# SIBG301M114KGH register map
Vendor: Silicon Labs; Series: Si; File version: B
Registers are 32-bit, read-write, reset 0x0 unless marked. A register's access mark holds for its fields unless they carry their own. Offsets are from the block's base; [hi:lo] are bit positions; lines under a group give offsets from that group; {n}, {i} and the like mark numbered series; 'fields as' and 'values as' point back to an identical list.

## GPIO_NS — GPIO_NS Registers
Base 0x4083C000
Same registers: GPIO_S 0x5083C000
0x00 IPVERSION ro reset 0x8
  [31:0] IPVERSION — ip version id
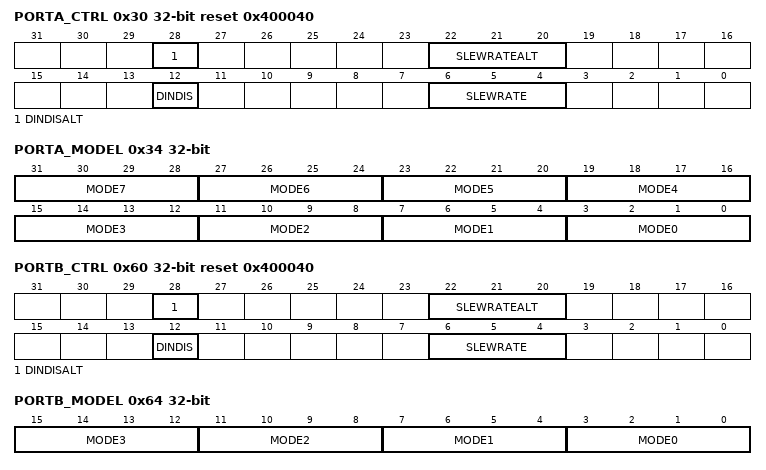
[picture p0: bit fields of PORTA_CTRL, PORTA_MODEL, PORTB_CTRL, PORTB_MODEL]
0x30 PORTA_CTRL reset 0x400040 — Port control
  [28] DINDISALT — Data In Disable Alt
  [22:20] SLEWRATEALT
  [12] DINDIS — Data In Disable
  [6:4] SLEWRATE
0x34 PORTA_MODEL — mode low
  [all] fields
    0=DISABLED (Input disabled. Pullup if DOUT is set.); 1=INPUT (Input enabled. Filter if DOUT is set.); 2=INPUTPULL (Input enabled. DOUT determines pull direction.); 3=INPUTPULLFILTER (Input enabled with filter. DOUT determines pull direction.); 4=PUSHPULL (Push-pull output.); 5=PUSHPULLALT (Push-pull using alternate control.); 6=WIREDOR (Wired-or output.); 7=WIREDORPULLDOWN (Wired-or output with pull-down.); 8=WIREDAND (Open-drain output.); 9=WIREDANDFILTER (Open-drain output with filter.); 10=WIREDANDPULLUP (Open-drain output with pullup.); 11=WIREDANDPULLUPFILTER (Open-drain output with filter and pullup.); 12=WIREDANDALT (Open-drain output using alternate control.); 13=WIREDANDALTFILTER (Open-drain output using alternate control with filter.); 14=WIREDANDALTPULLUP (Open-drain output using alternate control with pullup.); 15=WIREDANDALTPULLUPFILTER (Open-drain output using alternate control with filter and pullup.)
  [4n+3:4n] MODE{n} (n=0..7) — MODE n
0x3C PORTA_MODEH — mode high
  [3:0] MODE0 — MODE n
    values as the fields of PORTA_MODEL
0x40 PORTA_DOUT — data out
  [8:0] DOUT — Data output
0x44 PORTA_DIN ro — data in
  [8:0] DIN — Data input
0x48 PORTA_AMUXMODE — AMUXMODE
  [8:0] LNEN — Low Noise Enable
0x60 PORTB_CTRL reset 0x400040 — Port control
  fields as PORTA_CTRL
0x64 PORTB_MODEL — mode low
  [all] fields
    values as the fields of PORTA_MODEL
  [4n+3:4n] MODE{n} (n=0..3) — MODE n
0x70 PORTB_DOUT — data out
  [3:0] DOUT — Data output
0x74 PORTB_DIN ro — data in
  [3:0] DIN — Data input
0x78 PORTB_AMUXMODE — AMUXMODE
  [3:0] LNEN — Low Noise Enable
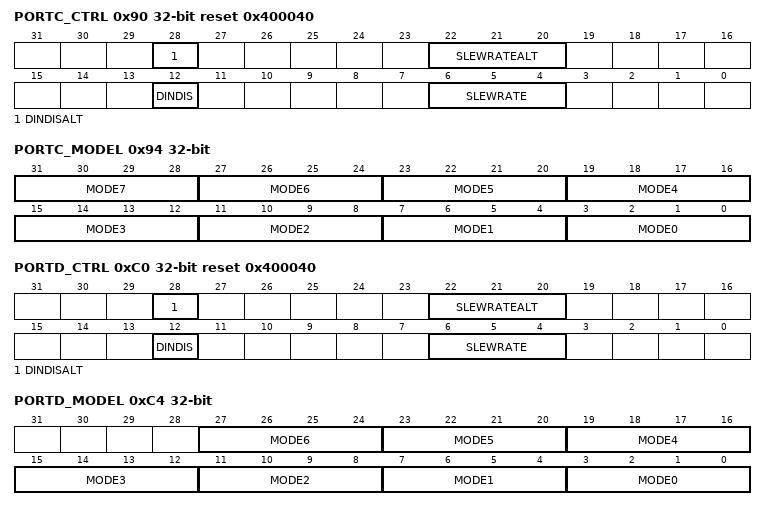
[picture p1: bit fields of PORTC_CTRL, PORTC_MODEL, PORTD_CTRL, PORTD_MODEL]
0x90 PORTC_CTRL reset 0x400040 — Port control
  fields as PORTA_CTRL
0x94 PORTC_MODEL — mode low
  fields as PORTA_MODEL
0xA0 PORTC_DOUT — data out
  [7:0] DOUT — Data output
0xA4 PORTC_DIN ro — data in
  [7:0] DIN — Data input
0xA8 PORTC_AMUXMODE — AMUXMODE
  [7:0] LNEN — Low Noise Enable
0xC0 PORTD_CTRL reset 0x400040 — Port control
  fields as PORTA_CTRL
0xC4 PORTD_MODEL — mode low
  [all] fields
    values as the fields of PORTA_MODEL
  [4n+3:4n] MODE{n} (n=0..6) — MODE n
0xD0 PORTD_DOUT — data out
  [6:0] DOUT — Data output
0xD4 PORTD_DIN ro — data in
  [6:0] DIN — Data input
0xD8 PORTD_AMUXMODE — AMUXMODE
  [6:0] LNEN — Low Noise Enable
0x300 LOCK wo reset 0xA534
  [15:0] LOCKKEY — Configuration Lock Key
    0xA534=UNLOCK (Unlock code)
0x310 GPIOLOCKSTATUS ro
  [0] LOCK — GPIO LOCK status
    0=UNLOCKED (Registers are unlocked); 1=LOCKED (Registers are locked)
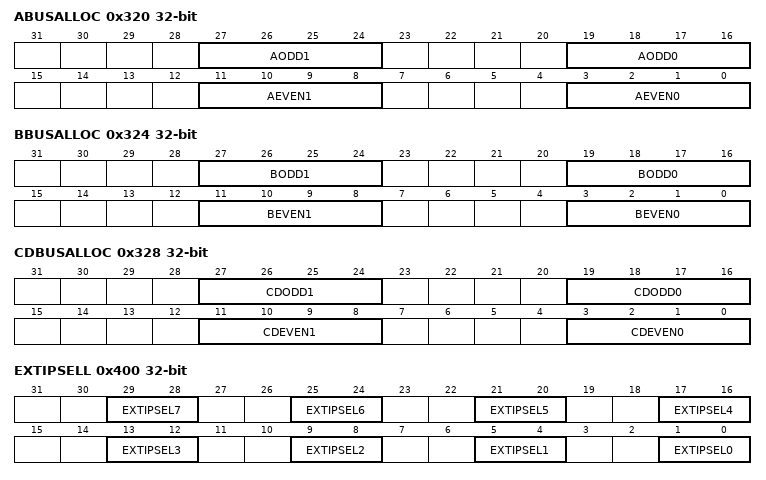
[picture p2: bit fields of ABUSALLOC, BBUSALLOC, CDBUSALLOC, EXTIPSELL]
0x320 ABUSALLOC — A Bus allocation
  [all] fields
    0=TRISTATE (The bus is not allocated); 1=ADC0 (The bus is allocated to ADC0); 2=ACMP0 (The bus is allocated to ACMP0); 3=ACMP1 (The bus is allocated to ACMP1)
  [27:24] AODD1 — A Bus Odd 1
  [19:16] AODD0 — A Bus Odd 0
  [11:8] AEVEN1 — A Bus Even 1
  [3:0] AEVEN0 — A Bus Even 0
0x324 BBUSALLOC — B Bus allocation
  [27:24] BODD1 — B Bus Odd 1
    0=TRISTATE (The bus is not allocated); 1=ADC0 (The bus is allocated to ADC0); 2=ACMP0 (The bus is allocated to ACMP0); 3=ACMP1 (The bus is allocated to ACMP1); 4=VDAC0CH1 (The bus is allocated to VDAC0 CH1); 5=VDAC1CH1 (The bus is allocated to VDAC1 CH1)
  [19:16] BODD0 — B Bus Odd 0
    0=TRISTATE (The bus is not allocated); 1=ADC0 (The bus is allocated to ADC0); 2=ACMP0 (The bus is allocated to ACMP0); 3=ACMP1 (The bus is allocated to ACMP1); 4=VDAC0CH0 (The bus is allocated to VDAC0 CH0); 5=VDAC1CH0 (The bus is allocated to VDAC1 CH0)
  [11:8] BEVEN1 — B Bus Even 1
    values as the fields of ABUSALLOC
  [3:0] BEVEN0 — B Bus Even 0
    0=TRISTATE (The bus is not allocated); 1=ADC0 (The bus is allocated to ADC0); 2=ACMP0 (The bus is allocated to ACMP0); 3=ACMP1 (The bus is allocated to ACMP1); 14=DIAGA (The bus is allocated to DIAGA)
0x328 CDBUSALLOC — CD Bus allocation
  [all] fields
    0=TRISTATE (The bus is not allocated); 1=ADC0 (The bus is allocated to ADC0); 2=ACMP0 (The bus is allocated to ACMP0); 3=ACMP1 (The bus is allocated to ACMP1); 4=LEDDRV (The bus is allocated to LEDDRV)
  [27:24] CDODD1 — CD Bus Odd 1
  [19:16] CDODD0 — CD Bus Odd 0
  [11:8] CDEVEN1 — CD Bus Even 1
  [3:0] CDEVEN0 — CD Bus Even 0
0x400 EXTIPSELL — External Interrupt Port Select Low
  [all] fields
    0=PORTA (Port A group selected); 1=PORTB (Port B group selected); 2=PORTC (Port C group selected); 3=PORTD (Port D group selected)
  [4n+1:4n] EXTIPSEL{n} (n=0..7) — External Interrupt Port Select
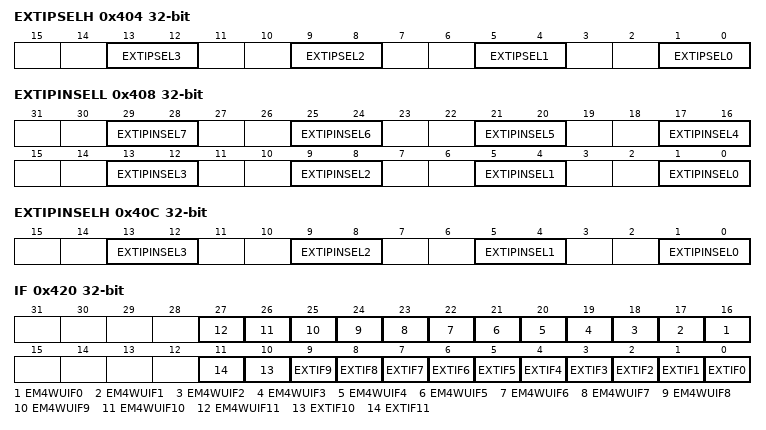
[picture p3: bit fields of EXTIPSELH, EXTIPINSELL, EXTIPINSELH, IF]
0x404 EXTIPSELH — External interrupt Port Select High
  [all] fields
    values as the fields of EXTIPSELL
  [4n+1:4n] EXTIPSEL{n} (n=0..3) — External Interrupt Port Select
0x408 EXTIPINSELL — External Interrupt Pin Select Low
  [all] fields
    {v}=PIN{v} (OFFSET={v}) (v=0..3)
  [4n+1:4n] EXTIPINSEL{n} (n=0..7) — External Interrupt Pin select
0x40C EXTIPINSELH — External Interrupt Pin Select High
  [all] fields
    {v}=PIN{v+8} (OFFSET={v+8}) (v=0..3)
  [4n+1:4n] EXTIPINSEL{n} (n=0..3) — External Interrupt Pin select
0x410 EXTIRISE — External Interrupt Rising Edge Trigger
  [11:0] EXTIRISE — EXT Int Rise
0x414 EXTIFALL — External Interrupt Falling Edge Trigger
  [11:0] EXTIFALL — EXT Int FALL
0x420 IF — Interrupt Flag
  [n+16] EM4WUIF{n} (n=0..11) — EM4 wake up
  [n] EXTIF{n} (n=0..11) — External Pin Flag
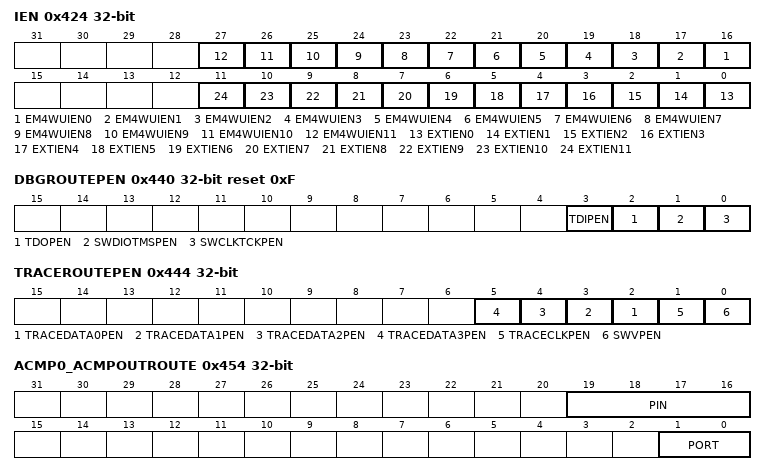
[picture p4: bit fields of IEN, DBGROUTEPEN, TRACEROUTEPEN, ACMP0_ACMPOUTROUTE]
0x424 IEN — Interrupt Enable
  [n+16] EM4WUIEN{n} (n=0..11) — EM4 Wake Up Interrupt En
  [n] EXTIEN{n} (n=0..11) — External Pin Enable
0x42C EM4WUEN
  [27:16] EM4WUEN — EM4 wake up enable
0x430 EM4WUPOL
  [27:16] EM4WUPOL — EM4 Wake-Up Polarity
0x440 DBGROUTEPEN reset 0xF
  [3] TDIPEN — JTAG Test Debug Input Pin Enable
  [2] TDOPEN — JTAG Test Debug Output Pin Enable
  [1] SWDIOTMSPEN — Route Location 0
  [0] SWCLKTCKPEN — Route Pin Enable
0x444 TRACEROUTEPEN
  [n+2] TRACEDATA{n}PEN (n=0..3) — Trace Data{n} Pin Enable
  [1] TRACECLKPEN — Trace Clk Pin Enable
  [0] SWVPEN — Serial Wire Viewer Output Pin Enable
0x450 ACMP0_ROUTEEN — ACMP0 pin enable
  [0] ACMPOUTPEN — ACMPOUT pin enable control bit
0x454 ACMP0_ACMPOUTROUTE — ACMPOUT port/pin select
  [19:16] PIN — ACMPOUT pin select register
  [1:0] PORT — ACMPOUT port select register
0x45C ACMP1_ROUTEEN — ACMP1 pin enable
  [0] ACMPOUTPEN — ACMPOUT pin enable control bit
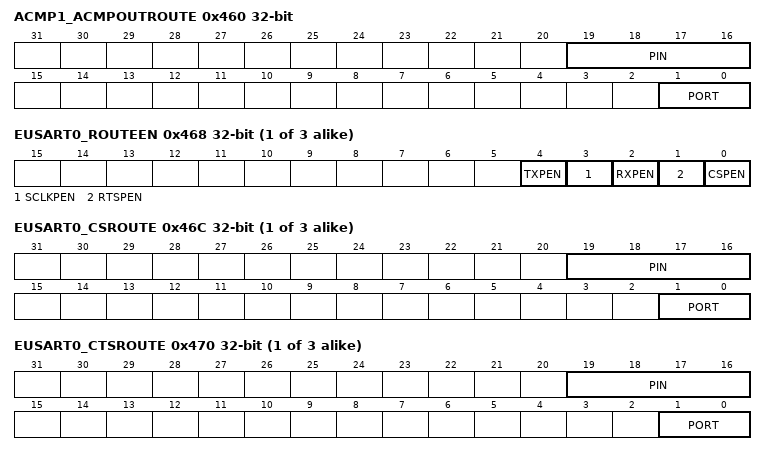
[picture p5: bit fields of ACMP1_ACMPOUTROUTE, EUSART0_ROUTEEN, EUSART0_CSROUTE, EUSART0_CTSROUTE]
0x460 ACMP1_ACMPOUTROUTE — ACMPOUT port/pin select
  fields as ACMP0_ACMPOUTROUTE
{0x468+0x20*i} EUSART{i}_ROUTEEN (i=0..2) — EUSART{i} pin enable
  [4] TXPEN — TX pin enable control bit
  [3] SCLKPEN — SCLK pin enable control bit
  [2] RXPEN — RX pin enable control bit
  [1] RTSPEN — RTS pin enable control bit
  [0] CSPEN — CS pin enable control bit
{0x46C+0x20*i} EUSART{i}_CSROUTE (i=0..2) — CS port/pin select
  [19:16] PIN — CS pin select register
  [1:0] PORT — CS port select register
{0x470+0x20*i} EUSART{i}_CTSROUTE (i=0..2) — CTS port/pin select
  [19:16] PIN — CTS pin select register
  [1:0] PORT — CTS port select register
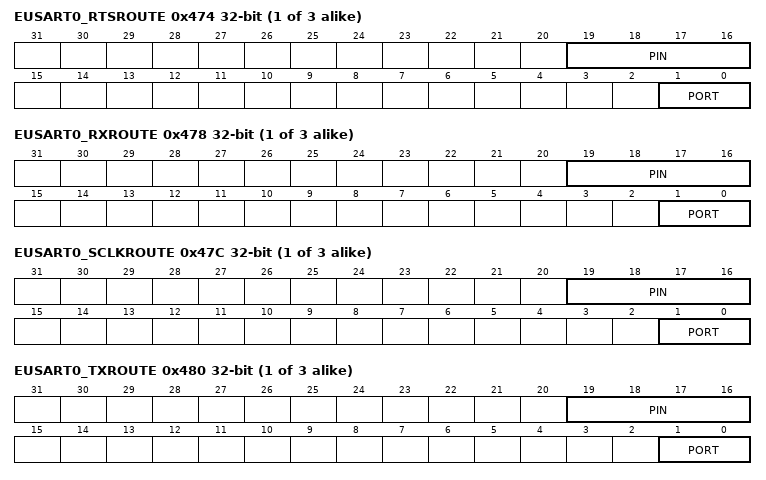
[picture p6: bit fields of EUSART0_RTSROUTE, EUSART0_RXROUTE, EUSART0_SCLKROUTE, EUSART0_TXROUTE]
{0x474+0x20*i} EUSART{i}_RTSROUTE (i=0..2) — RTS port/pin select
  [19:16] PIN — RTS pin select register
  [1:0] PORT — RTS port select register
{0x478+0x20*i} EUSART{i}_RXROUTE (i=0..2) — RX port/pin select
  [19:16] PIN — RX pin select register
  [1:0] PORT — RX port select register
{0x47C+0x20*i} EUSART{i}_SCLKROUTE (i=0..2) — SCLK port/pin select
  [19:16] PIN — SCLK pin select register
  [1:0] PORT — SCLK port select register
{0x480+0x20*i} EUSART{i}_TXROUTE (i=0..2) — TX port/pin select
  [19:16] PIN — TX pin select register
  [1:0] PORT — TX port select register
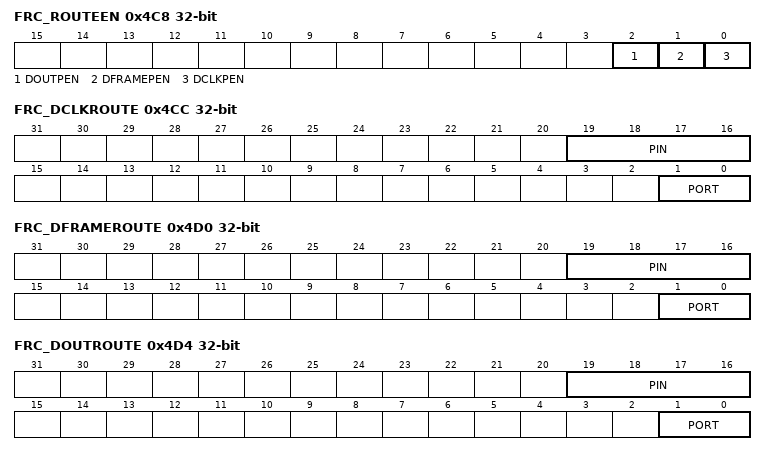
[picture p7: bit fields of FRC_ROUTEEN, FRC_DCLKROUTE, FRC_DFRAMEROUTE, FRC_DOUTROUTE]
0x4C8 FRC_ROUTEEN — FRC pin enable
  [2] DOUTPEN — DOUT pin enable control bit
  [1] DFRAMEPEN — DFRAME pin enable control bit
  [0] DCLKPEN — DCLK pin enable control bit
0x4CC FRC_DCLKROUTE — DCLK port/pin select
  [19:16] PIN — DCLK pin select register
  [1:0] PORT — DCLK port select register
0x4D0 FRC_DFRAMEROUTE — DFRAME port/pin select
  [19:16] PIN — DFRAME pin select register
  [1:0] PORT — DFRAME port select register
0x4D4 FRC_DOUTROUTE — DOUT port/pin select
  [19:16] PIN — DOUT pin select register
  [1:0] PORT — DOUT port select register
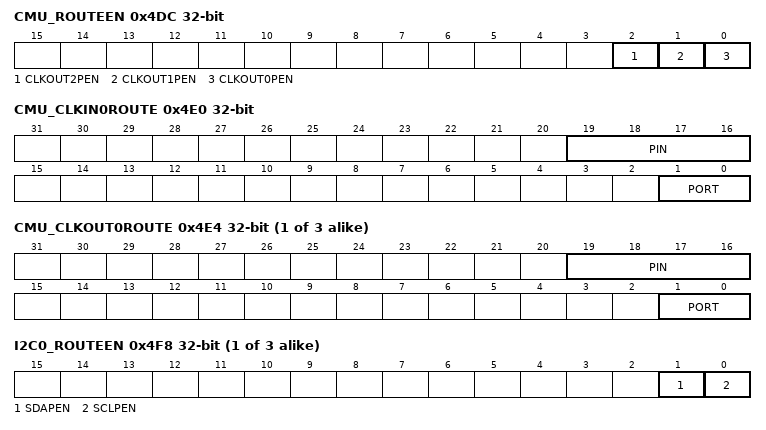
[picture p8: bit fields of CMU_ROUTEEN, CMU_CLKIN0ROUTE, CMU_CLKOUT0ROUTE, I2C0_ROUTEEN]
0x4DC CMU_ROUTEEN — HOSTCMU pin enable
  [2] CLKOUT2PEN — CLKOUT2 pin enable control bit
  [1] CLKOUT1PEN — CLKOUT1 pin enable control bit
  [0] CLKOUT0PEN — CLKOUT0 pin enable control bit
0x4E0 CMU_CLKIN0ROUTE — CLKIN0 port/pin select
  [19:16] PIN — CLKIN0 pin select register
  [1:0] PORT — CLKIN0 port select register
{0x4E4+4i} CMU_CLKOUT{i}ROUTE (i=0..2) — CLKOUT{i} port/pin select
  [19:16] PIN — CLKOUT{i} pin select register
  [1:0] PORT — CLKOUT{i} port select register
{0x4F8+0x10*i} I2C{i}_ROUTEEN (i=0..2) — I2C{i} pin enable
  [1] SDAPEN — SDA pin enable control bit
  [0] SCLPEN — SCL pin enable control bit
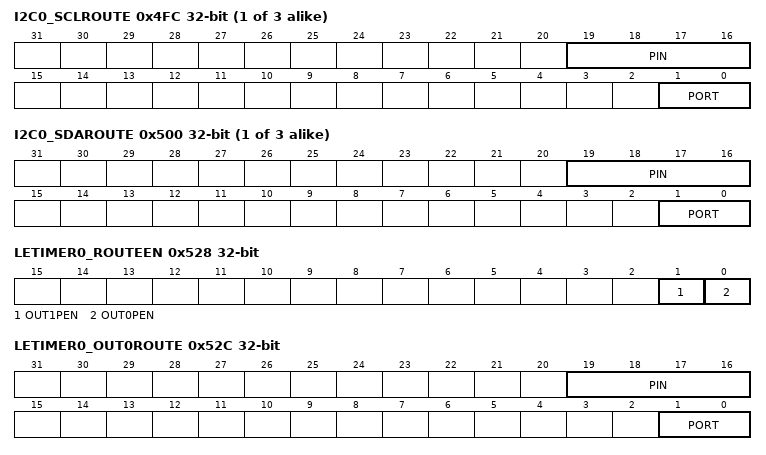
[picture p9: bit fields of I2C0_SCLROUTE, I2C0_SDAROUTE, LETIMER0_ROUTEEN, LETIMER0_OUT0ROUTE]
{0x4FC+0x10*i} I2C{i}_SCLROUTE (i=0..2) — SCL port/pin select
  [19:16] PIN — SCL pin select register
  [1:0] PORT — SCL port select register
{0x500+0x10*i} I2C{i}_SDAROUTE (i=0..2) — SDA port/pin select
  [19:16] PIN — SDA pin select register
  [1:0] PORT — SDA port select register
0x528 LETIMER0_ROUTEEN — LETIMER0 pin enable
  [1] OUT1PEN — OUT1 pin enable control bit
  [0] OUT0PEN — OUT0 pin enable control bit
0x52C LETIMER0_OUT0ROUTE — OUT0 port/pin select
  [19:16] PIN — OUT0 pin select register
  [1:0] PORT — OUT0 port select register
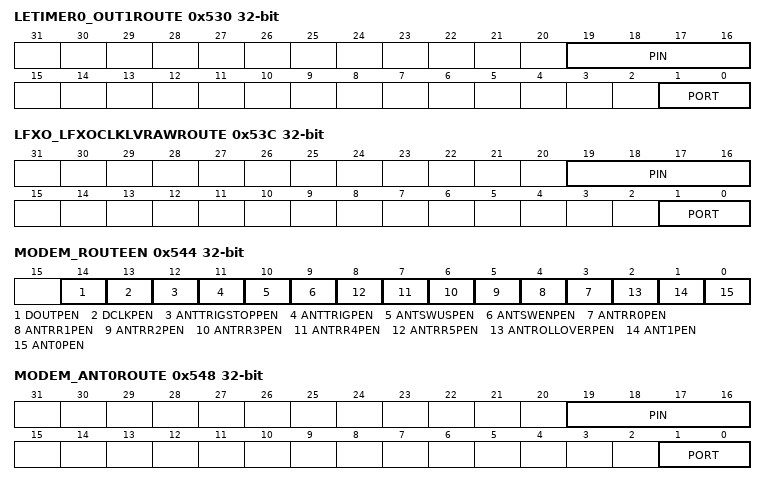
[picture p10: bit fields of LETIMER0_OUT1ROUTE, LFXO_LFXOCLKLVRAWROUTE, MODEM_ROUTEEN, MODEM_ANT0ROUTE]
0x530 LETIMER0_OUT1ROUTE — OUT1 port/pin select
  [19:16] PIN — OUT1 pin select register
  [1:0] PORT — OUT1 port select register
0x538 LFXO_ROUTEEN — LFXO pin enable
  [0] LFXOCLKLVRAWPEN — LFXOCLKLVRAW pin enable control bit
0x53C LFXO_LFXOCLKLVRAWROUTE — LFXOCLKLVRAW port/pin select
  [19:16] PIN — LFXOCLKLVRAW pin select register
  [1:0] PORT — LFXOCLKLVRAW port select register
0x544 MODEM_ROUTEEN — MODEM pin enable
  [14] DOUTPEN — DOUT pin enable control bit
  [13] DCLKPEN — DCLK pin enable control bit
  [12] ANTTRIGSTOPPEN — ANTTRIGSTOP pin enable control bit
  [11] ANTTRIGPEN — ANTTRIG pin enable control bit
  [10] ANTSWUSPEN — ANTSWUS pin enable control bit
  [9] ANTSWENPEN — ANTSWEN pin enable control bit
  [n+3] ANTRR{n}PEN (n=0..5) — ANTRR{n} pin enable control bit
  [2] ANTROLLOVERPEN — ANTROLLOVER pin enable control bit
  [1] ANT1PEN — ANT1 pin enable control bit
  [0] ANT0PEN — ANT0 pin enable control bit
0x548 MODEM_ANT0ROUTE — ANT0 port/pin select
  [19:16] PIN — ANT0 pin select register
  [1:0] PORT — ANT0 port select register
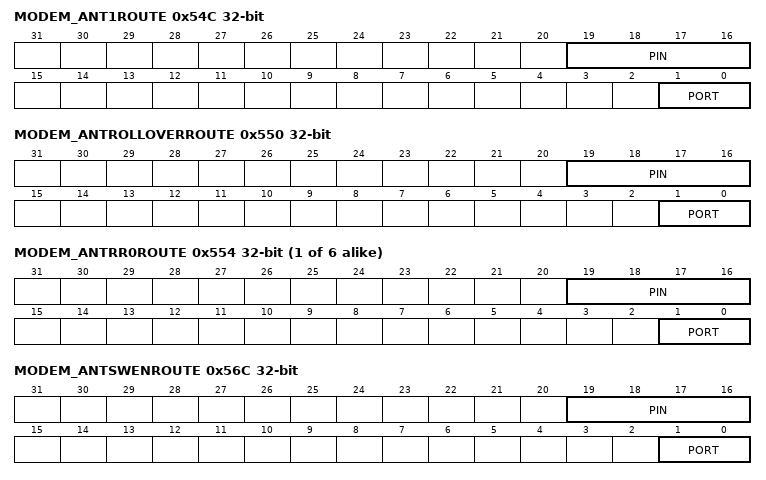
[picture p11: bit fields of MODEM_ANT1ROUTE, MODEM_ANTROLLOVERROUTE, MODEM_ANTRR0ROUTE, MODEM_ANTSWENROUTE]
0x54C MODEM_ANT1ROUTE — ANT1 port/pin select
  [19:16] PIN — ANT1 pin select register
  [1:0] PORT — ANT1 port select register
0x550 MODEM_ANTROLLOVERROUTE — ANTROLLOVER port/pin select
  [19:16] PIN — ANTROLLOVER pin select register
  [1:0] PORT — ANTROLLOVER port select register
{0x554+4i} MODEM_ANTRR{i}ROUTE (i=0..5) — ANTRR{i} port/pin select
  [19:16] PIN — ANTRR{i} pin select register
  [1:0] PORT — ANTRR{i} port select register
0x56C MODEM_ANTSWENROUTE — ANTSWEN port/pin select
  [19:16] PIN — ANTSWEN pin select register
  [1:0] PORT — ANTSWEN port select register
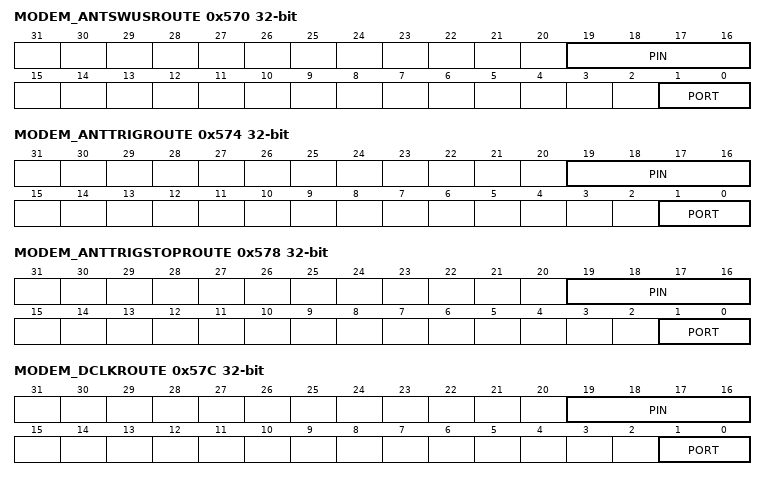
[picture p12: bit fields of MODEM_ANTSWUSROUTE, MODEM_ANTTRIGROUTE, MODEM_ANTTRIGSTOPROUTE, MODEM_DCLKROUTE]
0x570 MODEM_ANTSWUSROUTE — ANTSWUS port/pin select
  [19:16] PIN — ANTSWUS pin select register
  [1:0] PORT — ANTSWUS port select register
0x574 MODEM_ANTTRIGROUTE — ANTTRIG port/pin select
  [19:16] PIN — ANTTRIG pin select register
  [1:0] PORT — ANTTRIG port select register
0x578 MODEM_ANTTRIGSTOPROUTE — ANTTRIGSTOP port/pin select
  [19:16] PIN — ANTTRIGSTOP pin select register
  [1:0] PORT — ANTTRIGSTOP port select register
0x57C MODEM_DCLKROUTE — DCLK port/pin select
  fields as FRC_DCLKROUTE
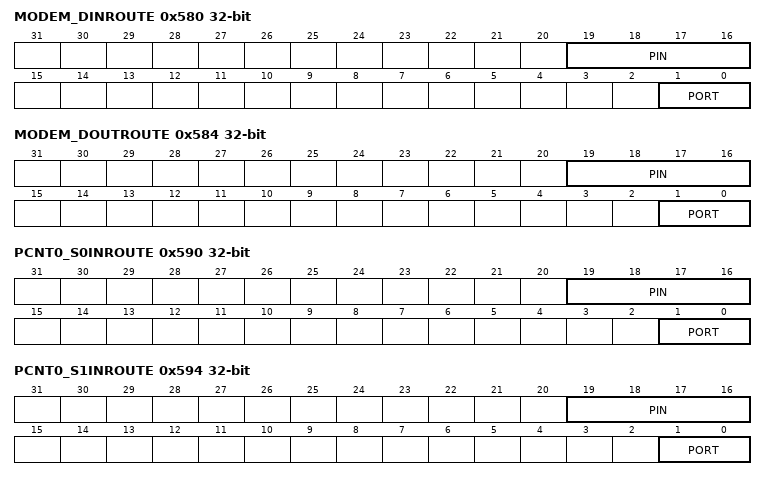
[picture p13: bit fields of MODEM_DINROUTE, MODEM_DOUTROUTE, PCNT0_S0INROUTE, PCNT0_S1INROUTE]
0x580 MODEM_DINROUTE — DIN port/pin select
  [19:16] PIN — DIN pin select register
  [1:0] PORT — DIN port select register
0x584 MODEM_DOUTROUTE — DOUT port/pin select
  fields as FRC_DOUTROUTE
0x590 PCNT0_S0INROUTE — S0IN port/pin select
  [19:16] PIN — S0IN pin select register
  [1:0] PORT — S0IN port select register
0x594 PCNT0_S1INROUTE — S1IN port/pin select
  [19:16] PIN — S1IN pin select register
  [1:0] PORT — S1IN port select register
0x59C PIXELRZ0_ROUTEEN — PIXELRZ0 pin enable
  [0] RZTXOUTPEN — RZTXOUT pin enable control bit
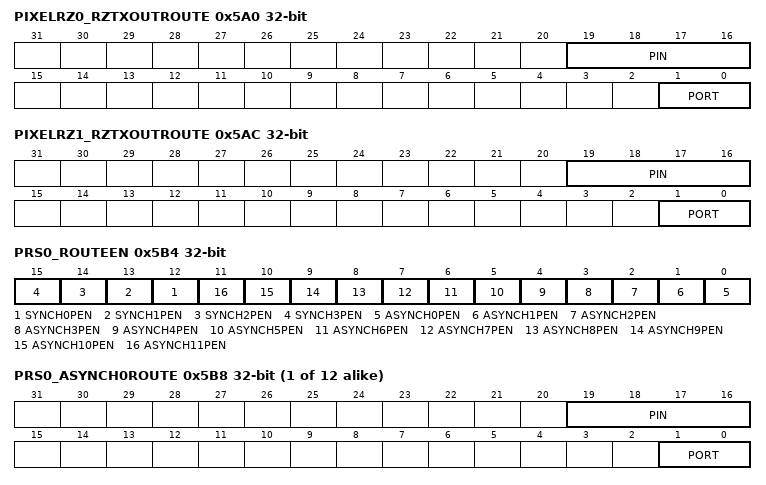
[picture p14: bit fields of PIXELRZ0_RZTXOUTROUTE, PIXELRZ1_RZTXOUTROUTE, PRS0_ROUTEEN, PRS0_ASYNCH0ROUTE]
0x5A0 PIXELRZ0_RZTXOUTROUTE — RZTXOUT port/pin select
  [19:16] PIN — RZTXOUT pin select register
  [1:0] PORT — RZTXOUT port select register
0x5A8 PIXELRZ1_ROUTEEN — PIXELRZ1 pin enable
  [0] RZTXOUTPEN — RZTXOUT pin enable control bit
0x5AC PIXELRZ1_RZTXOUTROUTE — RZTXOUT port/pin select
  fields as PIXELRZ0_RZTXOUTROUTE
0x5B4 PRS0_ROUTEEN — PRS0 pin enable
  [n+12] SYNCH{n}PEN (n=0..3) — SYNCH{n} pin enable control bit
  [n] ASYNCH{n}PEN (n=0..11) — ASYNCH{n} pin enable control bit
{0x5B8+4i} PRS0_ASYNCH{i}ROUTE (i=0..11) — ASYNCH{i} port/pin select
  [19:16] PIN — ASYNCH{i} pin select register
  [1:0] PORT — ASYNCH{i} port select register
{0x5E8+4i} PRS0_SYNCH{i}ROUTE (i=0..3) — SYNCH{i} port/pin select
  [19:16] PIN — SYNCH{i} pin select register
  [1:0] PORT — SYNCH{i} port select register
0x5FC RAC_ROUTEEN — RAC pin enable
  [1] PAENPEN — PAEN pin enable control bit
  [0] LNAENPEN — LNAEN pin enable control bit
0x600 RAC_LNAENROUTE — LNAEN port/pin select
  [19:16] PIN — LNAEN pin select register
  [1:0] PORT — LNAEN port select register
0x604 RAC_PAENROUTE — PAEN port/pin select
  [19:16] PIN — PAEN pin select register
  [1:0] PORT — PAEN port select register
0x668 TIMER0_ROUTEEN — TIMER0 pin enable
  [5] CCC2PEN — CDTI2 pin enable control bit
  [4] CCC1PEN — CDTI1 pin enable control bit
  [3] CCC0PEN — CDTI0 pin enable control bit
  [2] CC2PEN — CC2 pin enable control bit
  [1] CC1PEN — CC1 pin enable control bit
  [0] CC0PEN — CC0 pin enable control bit
{0x66C+4i} TIMER0_CC{i}ROUTE (i=0..2) — CC{i} port/pin select
  [19:16] PIN — CC{i} pin select register
  [1:0] PORT — CC{i} port select register
{0x678+4i} TIMER0_CDTI{i}ROUTE (i=0..2) — CDTI{i} port/pin select
  [19:16] PIN — CDTI{i} pin select register
  [1:0] PORT — CDTI{i} port select register
0x688 TIMER1_ROUTEEN — TIMER1 pin enable
  fields as TIMER0_ROUTEEN
{0x68C+4i} TIMER1_CC{i}ROUTE (i=0..2) — CC{i} port/pin select
  fields as TIMER0_CC0ROUTE
{0x698+4i} TIMER1_CDTI{i}ROUTE (i=0..2) — CDTI{i} port/pin select
  fields as TIMER0_CDTI0ROUTE
0x6A8 TIMER2_ROUTEEN — TIMER2 pin enable
  [n+7] CCC{n}PEN (n=0..6) — CDTI{n} pin enable control bit
  [n] CC{n}PEN (n=0..6) — CC{n} pin enable control bit
{0x6AC+4i} TIMER2_CC{i}ROUTE (i=0..6) — CC{i} port/pin select
  fields as TIMER0_CC0ROUTE
{0x6C8+4i} TIMER2_CDTI{i}ROUTE (i=0..6) — CDTI{i} port/pin select
  fields as TIMER0_CDTI0ROUTE
0x6E8 TIMER3_ROUTEEN — TIMER3 pin enable
  fields as TIMER2_ROUTEEN
{0x6EC+4i} TIMER3_CC{i}ROUTE (i=0..6) — CC{i} port/pin select
  fields as TIMER0_CC0ROUTE
{0x708+4i} TIMER3_CDTI{i}ROUTE (i=0..6) — CDTI{i} port/pin select
  fields as TIMER0_CDTI0ROUTE
